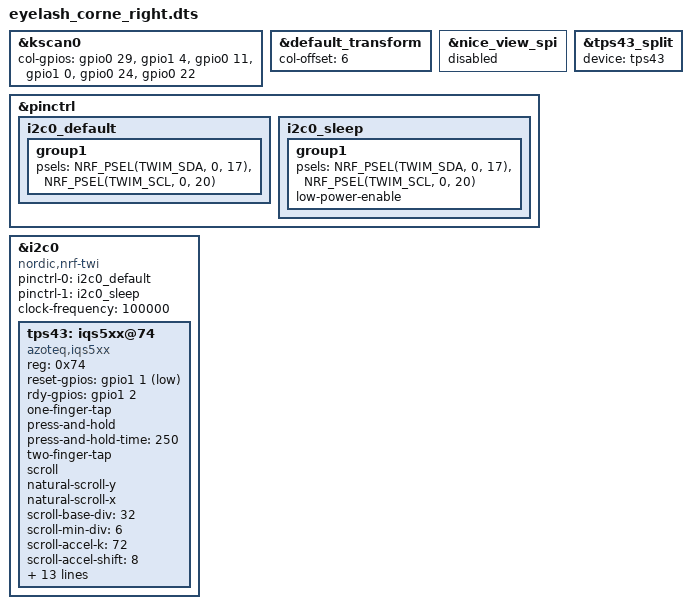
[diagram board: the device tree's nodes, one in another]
/*
*
* Copyright (c) 2024 The ZMK Contributors
* SPDX-License-Identifier: MIT
*
*/

#include "eyelash_corne.dtsi"

/* RIGHT half: same 6 key-matrix cols as the left, shifted into transform columns
 * 6..11 by col-offset (exactly like rolio's sofle_right.overlay). */
&kscan0 {
    col-gpios
        = <&gpio0 29 GPIO_ACTIVE_HIGH>   /* pro_micro 20 -> P0.29 */
        , <&gpio1 4  GPIO_ACTIVE_HIGH>   /* pro_micro 8  -> P1.04 */
        , <&gpio0 11 GPIO_ACTIVE_HIGH>   /* pro_micro 7  -> P0.11 */
        , <&gpio1 0  GPIO_ACTIVE_HIGH>   /* pro_micro 6  -> P1.00 */
        , <&gpio0 24 GPIO_ACTIVE_HIGH>   /* pro_micro 5  -> P0.24 */
        , <&gpio0 22 GPIO_ACTIVE_HIGH>   /* pro_micro 4  -> P0.22 */
        ;
};

&default_transform {
    col-offset = <6>;
};

/*
 * Azoteq IQS5xx (TPS65) touchpad -- RIGHT / peripheral half.
 *
 * Wired like the working LXF-YZP/zmk-config-rolio *master* branch (the config that
 * actually runs on this hardware; the tps65 branch's P0.15/P0.10 + RDY pull-down did
 * not):
 *   I2C0   SDA = P0.17,  SCL = P0.20      (400 kHz)
 *   RESET  = P1.01   (gpio1 1, active-low)
 *   RDY    = P1.02   (gpio1 2, active-high, no pull-down)
 *
 * P0.17/P0.20 are the display connector's pins: the LEFT half drives the vista508
 * display over SPI0 (SPIM0) on them; this half has no display, so we free SPI0 and
 * let I2C0 (TWIM0 -- the SAME nRF peripheral instance @0x40003000) own the pins.
 */

/* No display on this half: disable SPI0 so I2C0 can claim P0.17/P0.20. */
&nice_view_spi {
    status = "disabled";
};

&pinctrl {
    i2c0_default: i2c0_default {
        group1 {
            psels = <NRF_PSEL(TWIM_SDA, 0, 17)>,
                    <NRF_PSEL(TWIM_SCL, 0, 20)>;
        };
    };
    i2c0_sleep: i2c0_sleep {
        group1 {
            psels = <NRF_PSEL(TWIM_SDA, 0, 17)>,
                    <NRF_PSEL(TWIM_SCL, 0, 20)>;
            low-power-enable;
        };
    };
};

&i2c0 {
    /*
     * Legacy TWI (nordic,nrf-twi), NOT TWIM (EasyDMA), to match rolio EXACTLY.
     * rolio's &pro_micro_i2c resolves to nordic,nrf-twi @ 100 kHz. Forcing TWIM
     * here broke the touchpad the same way it broke the OLED: TWIM's EasyDMA cannot
     * transmit from flash/RODATA, so the Azoteq IQS5xx driver's const register
     * writes silently fail and the pad never comes up. Legacy TWI works (this is
     * why the touchpad only worked under rolio's firmware).
     */
    compatible = "nordic,nrf-twi";
    status = "okay";
    pinctrl-0 = <&i2c0_default>;
    pinctrl-1 = <&i2c0_sleep>;
    pinctrl-names = "default", "sleep";
    clock-frequency = <100000>;   /* I2C_BITRATE_STANDARD (100 kHz), as rolio */

    tps43: iqs5xx@74 {
        status = "okay";
        compatible = "azoteq,iqs5xx";
        reg = <0x74>;

        /* RESET / RDY: the pins that actually work on this hardware, taken from the
         * rolio MASTER branch (the tps65 pro_micro 21/16 = P0.15/P0.10 + RDY pull-down
         * did NOT work here). RESET = P1.01 (gpio1 1), RDY/INT = P1.02 (gpio1 2). */
        reset-gpios = <&gpio1 1 GPIO_ACTIVE_LOW>;    /* P1.01 */
        rdy-gpios   = <&gpio1 2 GPIO_ACTIVE_HIGH>;   /* P1.02 */

        /* Gestures the chip should report (rolio reference values). */
        one-finger-tap;
        press-and-hold;
        press-and-hold-time = <250>;
        two-finger-tap;

        scroll;
        /* Natural (content-follows-finger) scroll baseline (rolio parity). The
         * build-time master toggle is CONFIG_IQS5XX_NATURAL_SCROLL (driver Kconfig,
         * default y). Set CONFIG_IQS5XX_NATURAL_SCROLL=n in a .conf (e.g.
         * config/eyelash_corne_right.conf) to build classic/reverse scrolling.
         * (Devicetree can't read Kconfig -- it is processed first -- so the toggle
         * lives in the driver, not here.) */
        natural-scroll-y;
        natural-scroll-x;

        /* Scroll acceleration (velocity-lowered divisor). Defaults reproduce the
         * old linear feel at rest; the divisor drops as the finger speeds up so a
         * fast flick emits many more detents ("accelerator"). Tune on hardware:
         * raise scroll-accel-k / lower scroll-min-div for stronger acceleration. */
        scroll-base-div = <32>;      /* divisor at rest (units per detent) */
        scroll-min-div = <6>;        /* floor at top speed -> max accel = base/min */
        scroll-accel-k = <72>;       /* gain (Q8): higher = accelerates sooner */
        scroll-accel-shift = <8>;    /* fixed-point shift for scroll-accel-k */
        scroll-ema-shift = <2>;      /* velocity-EMA smoothing for inertia seed */

        /* Scroll inertia: content coasts after a fast lift-off, stops on next touch.
         * The coast runs on the touchpad's dedicated work queue (no I2C / no BLE
         * contention). Tune: raise fling-min to require a firmer flick, lower
         * fling-decay-num for a shorter coast. */
        scroll-inertia;
        fling-min = <6>;             /* min lift velocity to start a coast */
        fling-stop = <96>;           /* stop below 0.375 detent/tick (Q8) */
        fling-decay-num = <240>;     /* coast v *= 240/256 each tick (~1s) */
        fling-decay-den = <256>;
        fling-tick-ms = <16>;        /* >= BLE connection interval */

        /* Custom gestures (see driver Parts C & D). */
        zoom;                                  /* two-finger pinch-to-zoom */
        three-finger-swipe;                    /* three-finger swipe up -> launch app */
        three-finger-swipe-threshold = <80>;   /* tune: lower = more sensitive */

        /* Sensitivity (rolio reference values). */
        bottom-beta = <5>;
        stationary-threshold = <5>;

        /* Orientation -- adjust after first test (see guide section 9.3). */
        switch-xy;
    };
};

/* Peripheral side: forward this pointer device over the split link. */
&tps43_split {
    device = <&tps43>;
};
